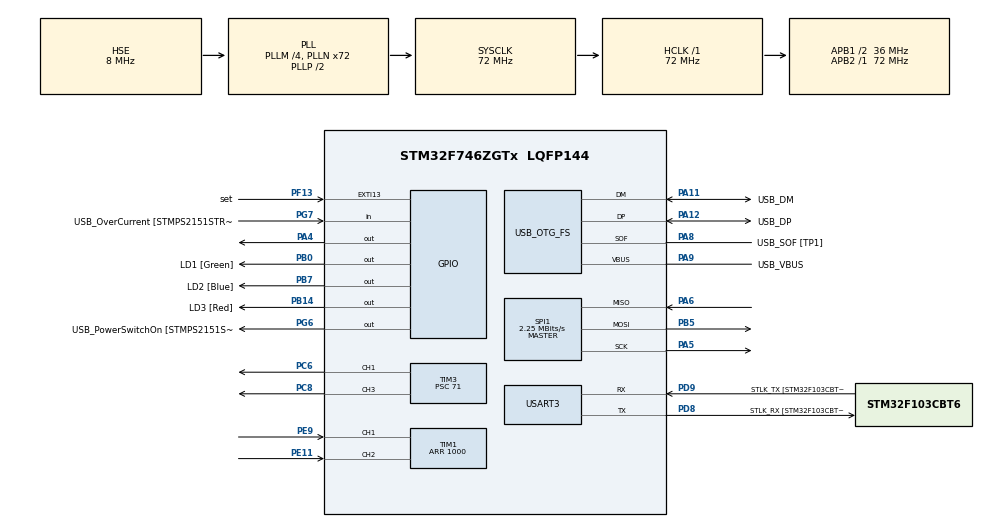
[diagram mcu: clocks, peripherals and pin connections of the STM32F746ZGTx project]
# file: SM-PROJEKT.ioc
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Mcu.Family=STM32F7
Mcu.Name=STM32F746ZGTx
Mcu.Package=LQFP144
NVIC.PriorityGroup=NVIC_PRIORITYGROUP_4
PA1.GPIO_Label=RMII_REF_CLK [LAN8742A-CZ-TR_REFCLK0]
PA1.Signal=ETH_REF_CLK
PA10.GPIO_Label=USB_ID
PA10.Signal=USB_OTG_FS_ID
PA11.GPIO_Label=USB_DM
PA11.Mode=Device_Only
PA11.Signal=USB_OTG_FS_DM
PA12.GPIO_Label=USB_DP
PA12.Mode=Device_Only
PA12.Signal=USB_OTG_FS_DP
PA13.GPIO_Label=TMS
PA13.Mode=Serial_Wire
PA13.Signal=SYS_JTMS-SWDIO
PA14.GPIO_Label=TCK
PA14.Mode=Serial_Wire
PA14.Signal=SYS_JTCK-SWCLK
PA2.GPIO_Label=RMII_MDIO [LAN8742A-CZ-TR_MDIO]
PA2.Signal=ETH_MDIO
PA4.Signal=GPIO_Output
PA5.Mode=Full_Duplex_Master
PA5.Signal=SPI1_SCK
PA6.Mode=Full_Duplex_Master
PA6.Signal=SPI1_MISO
PA7.GPIO_Label=RMII_CRS_DV [LAN8742A-CZ-TR_CRS_DV]
PA7.Signal=ETH_CRS_DV
PA8.GPIO_Label=USB_SOF [TP1]
PA8.Mode=Activate_SOF_FS
PA8.Signal=USB_OTG_FS_SOF
PA9.GPIO_Label=USB_VBUS
PA9.Mode=Activate_VBUS
PA9.Signal=USB_OTG_FS_VBUS
PB0.GPIO_Label=LD1 [Green]
PB0.Signal=GPIO_Output
PB13.GPIO_Label=RMII_TXD1 [LAN8742A-CZ-TR_TXD1]
PB13.Signal=ETH_TXD1
PB14.GPIO_Label=LD3 [Red]
PB14.Signal=GPIO_Output
PB3.GPIO_Label=SW0
PB3.Signal=SYS_JTDO-SWO
PB5.Mode=Full_Duplex_Master
PB5.Signal=SPI1_MOSI
PB7.GPIO_Label=LD2 [Blue]
PB7.Signal=GPIO_Output
PC1.GPIO_Label=RMII_MDC [LAN8742A-CZ-TR_MDC]
PC1.Signal=ETH_MDC
PC14/OSC32_IN.Mode=LSE-External-Oscillator
PC14/OSC32_IN.Signal=RCC_OSC32_IN
PC15/OSC32_OUT.Mode=LSE-External-Oscillator
PC15/OSC32_OUT.Signal=RCC_OSC32_OUT
PC4.GPIO_Label=RMII_RXD0 [LAN8742A-CZ-TR_RXD0]
PC4.Signal=ETH_RXD0
PC5.GPIO_Label=RMII_RXD1 [LAN8742A-CZ-TR_RXD1]
PC5.Signal=ETH_RXD1
PC6.Signal=S_TIM3_CH1
PC8.Signal=S_TIM3_CH3
PD8.GPIO_Label=STLK_RX [STM32F103CBT6_PA3]
PD8.GPIO_PuPd=GPIO_PULLUP
PD8.Mode=Asynchronous
PD8.Signal=USART3_TX
PD9.GPIO_Label=STLK_TX [STM32F103CBT6_PA2]
PD9.GPIO_PuPd=GPIO_PULLUP
PD9.Mode=Asynchronous
PD9.Signal=USART3_RX
PE11.Signal=S_TIM1_CH2
PE9.Signal=S_TIM1_CH1
PF13.GPIO_Label=set
PF13.GPIO_ModeDefaultEXTI=GPIO_MODE_IT_RISING_FALLING
PF13.Signal=GPXTI13
PG11.GPIO_Label=RMII_TX_EN [LAN8742A-CZ-TR_TXEN]
PG11.Signal=ETH_TX_EN
PG13.GPIO_Label=RMII_TXD0 [LAN8742A-CZ-TR_TXD0]
PG13.Signal=ETH_TXD0
PG6.GPIO_Label=USB_PowerSwitchOn [STMPS2151STR_EN]
PG6.Signal=GPIO_Output
PG7.GPIO_Label=USB_OverCurrent [STMPS2151STR_FAULT]
PG7.Signal=GPIO_Input
PH0/OSC_IN.GPIO_Label=MCO [STM32F103CBT6_PA8]
PH0/OSC_IN.Mode=HSE-External-Clock-Source
PH0/OSC_IN.Signal=RCC_OSC_IN
PH1/OSC_OUT.Mode=HSE-External-Clock-Source
PH1/OSC_OUT.Signal=RCC_OSC_OUT
ProjectManager.HeapSize=0x200
ProjectManager.StackSize=0x400
ProjectManager.TargetToolchain=STM32CubeIDE
RCC.48MHZClocksFreq_Value=24000000
RCC.AHBFreq_Value=72000000
RCC.APB1CLKDivider=RCC_HCLK_DIV2
RCC.APB1Freq_Value=36000000
RCC.APB1TimFreq_Value=72000000
RCC.APB2Freq_Value=72000000
RCC.APB2TimFreq_Value=72000000
RCC.CortexFreq_Value=72000000
RCC.HCLKFreq_Value=72000000
RCC.HSE_VALUE=8000000
RCC.HSI_VALUE=16000000
RCC.PLLM=4
RCC.PLLMUL=RCC_PLL_MUL9
RCC.PLLN=72
RCC.PLLQ=3
RCC.PRESCALERUSB=RCC_USBCLKSOURCE_PLL_DIV1_5
RCC.SYSCLKFreq_VALUE=72000000
RCC.SYSCLKSource=RCC_SYSCLKSOURCE_PLLCLK
RCC.SYSCLKSourceVirtual=RCC_SYSCLKSOURCE_PLLCLK
RCC.USBFreq_Value=48000000
RCC.VCOOutputFreq_Value=144000000
SH.S_TIM1_CH1.0=TIM1_CH1,Encoder_Interface
SH.S_TIM1_CH2.0=TIM1_CH2,Encoder_Interface
SH.S_TIM3_CH1.0=TIM3_CH1,PWM Generation1 CH1
SH.S_TIM3_CH3.0=TIM3_CH3,PWM Generation3 CH3
SPI1.BaudRatePrescaler=SPI_BAUDRATEPRESCALER_32
SPI1.CLKPhase=SPI_PHASE_1EDGE
SPI1.CLKPolarity=SPI_POLARITY_LOW
SPI1.CalculateBaudRate=2.25 MBits/s
SPI1.DataSize=SPI_DATASIZE_8BIT
SPI1.Direction=SPI_DIRECTION_2LINES
SPI1.Mode=SPI_MODE_MASTER
SPI1.VirtualType=VM_MASTER
TIM1.EncoderMode=TIM_ENCODERMODE_TI1
TIM1.IC1Filter=0
TIM1.IC2Filter=0
TIM1.Period=1000
TIM3.AutoReloadPreload=TIM_AUTORELOAD_PRELOAD_DISABLE
TIM3.Channel-PWM\ Generation1\ CH1=TIM_CHANNEL_1
TIM3.Channel-PWM\ Generation3\ CH3=TIM_CHANNEL_3
TIM3.Period=999
TIM3.Prescaler=71
TIM3.Pulse-PWM\ Generation1\ CH1=1000
TIM3.Pulse-PWM\ Generation3\ CH3=1000
USART3.VirtualMode-Asynchronous=VM_ASYNC
USB_OTG_FS.VirtualMode=Device_Only
board=NUCLEO-F746ZG

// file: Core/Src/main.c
/* USER CODE BEGIN Header */
/**
  ******************************************************************************
  * @file           : main.c
  * @brief          : Main program body
  ******************************************************************************
  * @attention
  *
  * Copyright (c) 2025 STMicroelectronics.
  * All rights reserved.
  *
  * This software is licensed under terms that can be found in the LICENSE file
  * in the root directory of this software component.
  * If no LICENSE file comes with this software, it is provided AS-IS.
  *
  ******************************************************************************
  */
/* USER CODE END Header */
#include "main.h"

/* USER CODE BEGIN Includes */
#include "arm_math.h"
#include "BMPXX80.h"
#include "pid.h"

/* USER CODE END Includes */

SPI_HandleTypeDef hspi1;

TIM_HandleTypeDef htim1;
TIM_HandleTypeDef htim3;

UART_HandleTypeDef huart3;

PCD_HandleTypeDef hpcd_USB_OTG_FS;

/* USER CODE BEGIN PV */

// UART
	uint8_t temp_size;
	char buffer[100];
	char msg[3];
	float set_temp_interrupt;

// Temperatura
    float temp=0;
    float set_temp=38;
    float temperature=0;
    float pressure=0;

// PWM
	float duty;

// Nastawy PID
    float set_kp = 100.0f;
    float set_ki = 0.1f;
    float set_kd = 0.0f;
	float error=0;
	float u_1=0;
    float u=0;
    float prev_u=0;

/* USER CODE END PV */

void SystemClock_Config(void);
static void MX_GPIO_Init(void);
static void MX_USART3_UART_Init(void);
static void MX_USB_OTG_FS_PCD_Init(void);
static void MX_SPI1_Init(void);
static void MX_TIM3_Init(void);
static void MX_TIM1_Init(void);

/* USER CODE BEGIN 0 */
//res_str R10OHM;
/* USER CODE END 0 */

int main(void)
{

  /* MCU Configuration--------------------------------------------------------*/

  /* Reset of all peripherals, Initializes the Flash interface and the Systick. */
  HAL_Init();

  /* Configure the system clock */
  SystemClock_Config();

  /* Initialize all configured peripherals */
  MX_GPIO_Init();
  MX_USART3_UART_Init();
  MX_USB_OTG_FS_PCD_Init();
  MX_SPI1_Init();
  MX_TIM3_Init();
  MX_TIM1_Init();
  /* USER CODE BEGIN 2 */

  HAL_TIM_PWM_Start(&htim3, TIM_CHANNEL_3);
  HAL_TIM_PWM_Start(&htim3, TIM_CHANNEL_1);
  BMP280_Init(&hspi1, BMP280_TEMPERATURE_16BIT, BMP280_STANDARD, BMP280_FORCEDMODE);
  #define BMP_CS_GPIO_Port GPIOA
  #define BMP_CS_Pin GPIO_PIN_4

  arm_pid_instance_f32 pid;
  pid.Kp=set_kp;
  pid.Kd=set_kd;
  pid.Ki=set_ki;
  arm_pid_init_f32(&pid, 1);

  /* USER CODE END 2 */

  /* Infinite loop */
  while (1)
  {

    /* USER CODE BEGIN 3 */

	  	pid.Kp=set_kp;
	  	pid.Kd=set_kd;
	  	pid.Ki=set_ki;

	  HAL_GPIO_WritePin(BMP_CS_GPIO_Port, BMP_CS_Pin, GPIO_PIN_RESET);
	  BMP280_ReadTemperatureAndPressure(&temp, &pressure);
	  HAL_GPIO_WritePin(BMP_CS_GPIO_Port, BMP_CS_Pin, GPIO_PIN_SET);

	  		error = (set_temp-temp);

	  		u = arm_pid_f32(&pid, error);

	  		temp_size=sprintf(&buffer, "Temperatura: %f \n\r",temp);
	  		HAL_UART_Transmit(&huart3, (uint8_t*)buffer, temp_size, 0xffff);
	  		HAL_UART_Receive_IT(&huart3, &msg, 2);

	  		if(u<0.0){
	  			u=0.0;
	  		}
	  		if(u >1000.0){
	  			u=1000.0;
	  		}

	  		__HAL_TIM_SET_COMPARE(&htim3, TIM_CHANNEL_1,u);
	  		HAL_Delay(100);

  }
  /* USER CODE END 3 */
}

void SystemClock_Config(void)
{
  RCC_OscInitTypeDef RCC_OscInitStruct = {0};
  RCC_ClkInitTypeDef RCC_ClkInitStruct = {0};

  /** Configure LSE Drive Capability
  */
  HAL_PWR_EnableBkUpAccess();

  /** Configure the main internal regulator output voltage
  */
  __HAL_RCC_PWR_CLK_ENABLE();
  __HAL_PWR_VOLTAGESCALING_CONFIG(PWR_REGULATOR_VOLTAGE_SCALE3);

  /** Initializes the RCC Oscillators according to the specified parameters
  * in the RCC_OscInitTypeDef structure.
  */
  RCC_OscInitStruct.OscillatorType = RCC_OSCILLATORTYPE_HSE;
  RCC_OscInitStruct.HSEState = RCC_HSE_BYPASS;
  RCC_OscInitStruct.PLL.PLLState = RCC_PLL_ON;
  RCC_OscInitStruct.PLL.PLLSource = RCC_PLLSOURCE_HSE;
  RCC_OscInitStruct.PLL.PLLM = 4;
  RCC_OscInitStruct.PLL.PLLN = 72;
  RCC_OscInitStruct.PLL.PLLP = RCC_PLLP_DIV2;
  RCC_OscInitStruct.PLL.PLLQ = 3;
  if (HAL_RCC_OscConfig(&RCC_OscInitStruct) != HAL_OK)
  {
    Error_Handler();
  }

  /** Initializes the CPU, AHB and APB buses clocks
  */
  RCC_ClkInitStruct.ClockType = RCC_CLOCKTYPE_HCLK|RCC_CLOCKTYPE_SYSCLK
                              |RCC_CLOCKTYPE_PCLK1|RCC_CLOCKTYPE_PCLK2;
  RCC_ClkInitStruct.SYSCLKSource = RCC_SYSCLKSOURCE_PLLCLK;
  RCC_ClkInitStruct.AHBCLKDivider = RCC_SYSCLK_DIV1;
  RCC_ClkInitStruct.APB1CLKDivider = RCC_HCLK_DIV2;
  RCC_ClkInitStruct.APB2CLKDivider = RCC_HCLK_DIV1;

  if (HAL_RCC_ClockConfig(&RCC_ClkInitStruct, FLASH_LATENCY_2) != HAL_OK)
  {
    Error_Handler();
  }
}

static void MX_SPI1_Init(void)
{

  /* SPI1 parameter configuration*/
  hspi1.Instance = SPI1;
  hspi1.Init.Mode = SPI_MODE_MASTER;
  hspi1.Init.Direction = SPI_DIRECTION_2LINES;
  hspi1.Init.DataSize = SPI_DATASIZE_8BIT;
  hspi1.Init.CLKPolarity = SPI_POLARITY_LOW;
  hspi1.Init.CLKPhase = SPI_PHASE_1EDGE;
  hspi1.Init.NSS = SPI_NSS_SOFT;
  hspi1.Init.BaudRatePrescaler = SPI_BAUDRATEPRESCALER_32;
  hspi1.Init.FirstBit = SPI_FIRSTBIT_MSB;
  hspi1.Init.TIMode = SPI_TIMODE_DISABLE;
  hspi1.Init.CRCCalculation = SPI_CRCCALCULATION_DISABLE;
  hspi1.Init.CRCPolynomial = 7;
  hspi1.Init.CRCLength = SPI_CRC_LENGTH_DATASIZE;
  hspi1.Init.NSSPMode = SPI_NSS_PULSE_ENABLE;
  if (HAL_SPI_Init(&hspi1) != HAL_OK)
  {
    Error_Handler();
  }

}

static void MX_TIM1_Init(void)
{

  TIM_Encoder_InitTypeDef sConfig = {0};
  TIM_MasterConfigTypeDef sMasterConfig = {0};

  htim1.Instance = TIM1;
  htim1.Init.Prescaler = 0;
  htim1.Init.CounterMode = TIM_COUNTERMODE_UP;
  htim1.Init.Period = 1000;
  htim1.Init.ClockDivision = TIM_CLOCKDIVISION_DIV1;
  htim1.Init.RepetitionCounter = 0;
  htim1.Init.AutoReloadPreload = TIM_AUTORELOAD_PRELOAD_DISABLE;
  sConfig.EncoderMode = TIM_ENCODERMODE_TI12;
  sConfig.IC1Polarity = TIM_ICPOLARITY_RISING;
  sConfig.IC1Selection = TIM_ICSELECTION_DIRECTTI;
  sConfig.IC1Prescaler = TIM_ICPSC_DIV1;
  sConfig.IC1Filter = 15;
  sConfig.IC2Polarity = TIM_ICPOLARITY_RISING;
  sConfig.IC2Selection = TIM_ICSELECTION_DIRECTTI;
  sConfig.IC2Prescaler = TIM_ICPSC_DIV1;
  sConfig.IC2Filter = 15;
  if (HAL_TIM_Encoder_Init(&htim1, &sConfig) != HAL_OK)
  {
    Error_Handler();
  }
  sMasterConfig.MasterOutputTrigger = TIM_TRGO_RESET;
  sMasterConfig.MasterOutputTrigger2 = TIM_TRGO2_RESET;
  sMasterConfig.MasterSlaveMode = TIM_MASTERSLAVEMODE_DISABLE;
  if (HAL_TIMEx_MasterConfigSynchronization(&htim1, &sMasterConfig) != HAL_OK)
  {
    Error_Handler();
  }

}

static void MX_TIM3_Init(void)
{

  TIM_MasterConfigTypeDef sMasterConfig = {0};
  TIM_OC_InitTypeDef sConfigOC = {0};

  htim3.Instance = TIM3;
  htim3.Init.Prescaler = 71;
  htim3.Init.CounterMode = TIM_COUNTERMODE_UP;
  htim3.Init.Period = 999;
  htim3.Init.ClockDivision = TIM_CLOCKDIVISION_DIV1;
  htim3.Init.AutoReloadPreload = TIM_AUTORELOAD_PRELOAD_DISABLE;
  if (HAL_TIM_PWM_Init(&htim3) != HAL_OK)
  {
    Error_Handler();
  }
  sMasterConfig.MasterOutputTrigger = TIM_TRGO_RESET;
  sMasterConfig.MasterSlaveMode = TIM_MASTERSLAVEMODE_DISABLE;
  if (HAL_TIMEx_MasterConfigSynchronization(&htim3, &sMasterConfig) != HAL_OK)
  {
    Error_Handler();
  }
  sConfigOC.OCMode = TIM_OCMODE_PWM1;
  sConfigOC.Pulse = 1000;
  sConfigOC.OCPolarity = TIM_OCPOLARITY_HIGH;
  sConfigOC.OCFastMode = TIM_OCFAST_DISABLE;
  if (HAL_TIM_PWM_ConfigChannel(&htim3, &sConfigOC, TIM_CHANNEL_1) != HAL_OK)
  {
    Error_Handler();
  }
  if (HAL_TIM_PWM_ConfigChannel(&htim3, &sConfigOC, TIM_CHANNEL_3) != HAL_OK)
  {
    Error_Handler();
  }
  HAL_TIM_MspPostInit(&htim3);

}

static void MX_USART3_UART_Init(void)
{

  huart3.Instance = USART3;
  huart3.Init.BaudRate = 115200;
  huart3.Init.WordLength = UART_WORDLENGTH_8B;
  huart3.Init.StopBits = UART_STOPBITS_1;
  huart3.Init.Parity = UART_PARITY_NONE;
  huart3.Init.Mode = UART_MODE_TX_RX;
  huart3.Init.HwFlowCtl = UART_HWCONTROL_NONE;
  huart3.Init.OverSampling = UART_OVERSAMPLING_16;
  huart3.Init.OneBitSampling = UART_ONE_BIT_SAMPLE_DISABLE;
  huart3.AdvancedInit.AdvFeatureInit = UART_ADVFEATURE_NO_INIT;
  if (HAL_UART_Init(&huart3) != HAL_OK)
  {
    Error_Handler();
  }

}

static void MX_USB_OTG_FS_PCD_Init(void)
{

  hpcd_USB_OTG_FS.Instance = USB_OTG_FS;
  hpcd_USB_OTG_FS.Init.dev_endpoints = 6;
  hpcd_USB_OTG_FS.Init.speed = PCD_SPEED_FULL;
  hpcd_USB_OTG_FS.Init.dma_enable = DISABLE;
  hpcd_USB_OTG_FS.Init.phy_itface = PCD_PHY_EMBEDDED;
  hpcd_USB_OTG_FS.Init.Sof_enable = ENABLE;
  hpcd_USB_OTG_FS.Init.low_power_enable = DISABLE;
  hpcd_USB_OTG_FS.Init.lpm_enable = DISABLE;
  hpcd_USB_OTG_FS.Init.vbus_sensing_enable = ENABLE;
  hpcd_USB_OTG_FS.Init.use_dedicated_ep1 = DISABLE;
  if (HAL_PCD_Init(&hpcd_USB_OTG_FS) != HAL_OK)
  {
    Error_Handler();
  }

}

static void MX_GPIO_Init(void)
{
  GPIO_InitTypeDef GPIO_InitStruct = {0};

  /* GPIO Ports Clock Enable */
  __HAL_RCC_GPIOC_CLK_ENABLE();
  __HAL_RCC_GPIOH_CLK_ENABLE();
  __HAL_RCC_GPIOA_CLK_ENABLE();
  __HAL_RCC_GPIOB_CLK_ENABLE();
  __HAL_RCC_GPIOE_CLK_ENABLE();
  __HAL_RCC_GPIOD_CLK_ENABLE();
  __HAL_RCC_GPIOG_CLK_ENABLE();

  /*Configure GPIO pin Output Level */
  HAL_GPIO_WritePin(GPIOA, GPIO_PIN_4, GPIO_PIN_RESET);

  /*Configure GPIO pin Output Level */
  HAL_GPIO_WritePin(GPIOB, LD1_Pin|LD3_Pin|LD2_Pin, GPIO_PIN_RESET);

  /*Configure GPIO pin Output Level */
  HAL_GPIO_WritePin(USB_PowerSwitchOn_GPIO_Port, USB_PowerSwitchOn_Pin, GPIO_PIN_RESET);

  /*Configure GPIO pin : USER_Btn_Pin */
  GPIO_InitStruct.Pin = USER_Btn_Pin;
  GPIO_InitStruct.Mode = GPIO_MODE_IT_RISING;
  GPIO_InitStruct.Pull = GPIO_NOPULL;
  HAL_GPIO_Init(USER_Btn_GPIO_Port, &GPIO_InitStruct);

  /*Configure GPIO pins : RMII_MDC_Pin RMII_RXD0_Pin RMII_RXD1_Pin */
  GPIO_InitStruct.Pin = RMII_MDC_Pin|RMII_RXD0_Pin|RMII_RXD1_Pin;
  GPIO_InitStruct.Mode = GPIO_MODE_AF_PP;
  GPIO_InitStruct.Pull = GPIO_NOPULL;
  GPIO_InitStruct.Speed = GPIO_SPEED_FREQ_VERY_HIGH;
  GPIO_InitStruct.Alternate = GPIO_AF11_ETH;
  HAL_GPIO_Init(GPIOC, &GPIO_InitStruct);

  /*Configure GPIO pins : RMII_REF_CLK_Pin RMII_MDIO_Pin RMII_CRS_DV_Pin */
  GPIO_InitStruct.Pin = RMII_REF_CLK_Pin|RMII_MDIO_Pin|RMII_CRS_DV_Pin;
  GPIO_InitStruct.Mode = GPIO_MODE_AF_PP;
  GPIO_InitStruct.Pull = GPIO_NOPULL;
  GPIO_InitStruct.Speed = GPIO_SPEED_FREQ_VERY_HIGH;
  GPIO_InitStruct.Alternate = GPIO_AF11_ETH;
  HAL_GPIO_Init(GPIOA, &GPIO_InitStruct);

  /*Configure GPIO pin : PA4 */
  GPIO_InitStruct.Pin = GPIO_PIN_4;
  GPIO_InitStruct.Mode = GPIO_MODE_OUTPUT_PP;
  GPIO_InitStruct.Pull = GPIO_NOPULL;
  GPIO_InitStruct.Speed = GPIO_SPEED_FREQ_LOW;
  HAL_GPIO_Init(GPIOA, &GPIO_InitStruct);

  /*Configure GPIO pins : LD1_Pin LD3_Pin LD2_Pin */
  GPIO_InitStruct.Pin = LD1_Pin|LD3_Pin|LD2_Pin;
  GPIO_InitStruct.Mode = GPIO_MODE_OUTPUT_PP;
  GPIO_InitStruct.Pull = GPIO_NOPULL;
  GPIO_InitStruct.Speed = GPIO_SPEED_FREQ_LOW;
  HAL_GPIO_Init(GPIOB, &GPIO_InitStruct);

  /*Configure GPIO pin : RMII_TXD1_Pin */
  GPIO_InitStruct.Pin = RMII_TXD1_Pin;
  GPIO_InitStruct.Mode = GPIO_MODE_AF_PP;
  GPIO_InitStruct.Pull = GPIO_NOPULL;
  GPIO_InitStruct.Speed = GPIO_SPEED_FREQ_VERY_HIGH;
  GPIO_InitStruct.Alternate = GPIO_AF11_ETH;
  HAL_GPIO_Init(RMII_TXD1_GPIO_Port, &GPIO_InitStruct);

  /*Configure GPIO pin : USB_PowerSwitchOn_Pin */
  GPIO_InitStruct.Pin = USB_PowerSwitchOn_Pin;
  GPIO_InitStruct.Mode = GPIO_MODE_OUTPUT_PP;
  GPIO_InitStruct.Pull = GPIO_NOPULL;
  GPIO_InitStruct.Speed = GPIO_SPEED_FREQ_LOW;
  HAL_GPIO_Init(USB_PowerSwitchOn_GPIO_Port, &GPIO_InitStruct);

  /*Configure GPIO pin : USB_OverCurrent_Pin */
  GPIO_InitStruct.Pin = USB_OverCurrent_Pin;
  GPIO_InitStruct.Mode = GPIO_MODE_INPUT;
  GPIO_InitStruct.Pull = GPIO_NOPULL;
  HAL_GPIO_Init(USB_OverCurrent_GPIO_Port, &GPIO_InitStruct);

  /*Configure GPIO pins : RMII_TX_EN_Pin RMII_TXD0_Pin */
  GPIO_InitStruct.Pin = RMII_TX_EN_Pin|RMII_TXD0_Pin;
  GPIO_InitStruct.Mode = GPIO_MODE_AF_PP;
  GPIO_InitStruct.Pull = GPIO_NOPULL;
  GPIO_InitStruct.Speed = GPIO_SPEED_FREQ_VERY_HIGH;
  GPIO_InitStruct.Alternate = GPIO_AF11_ETH;
  HAL_GPIO_Init(GPIOG, &GPIO_InitStruct);

}

void Error_Handler(void)
{
  __disable_irq();
  while (1)
  {
  }
}
